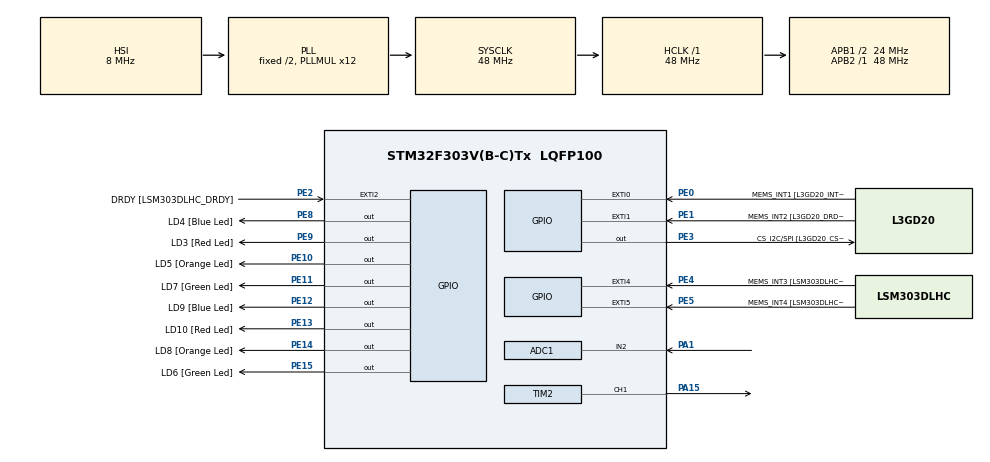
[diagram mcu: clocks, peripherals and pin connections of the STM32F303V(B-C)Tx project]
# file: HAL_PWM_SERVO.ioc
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ADC1.Channel-2\#ChannelRegularConversion=ADC_CHANNEL_2
ADC1.ContinuousConvMode=DISABLE
ADC1.DMAContinuousRequests=ENABLE
ADC1.EnableInjectedConversion=DISABLE
ADC1.ExternalTrigConv=ADC_EXTERNALTRIGCONV_T4_CC4
ADC1.NbrOfConversionFlag=1
ADC1.Offset-2\#ChannelRegularConversion=0
ADC1.OffsetNumber-2\#ChannelRegularConversion=ADC_OFFSET_NONE
ADC1.Rank-2\#ChannelRegularConversion=1
ADC1.Rank1_Channel=ADC_CHANNEL_2
ADC1.SamplingTime-2\#ChannelRegularConversion=ADC_SAMPLETIME_19CYCLES_5
ADC1.SamplingTimeOPAMP-2\#ChannelRegularConversion=ADC_SAMPLETIME_19CYCLES_5
ADC1.master=1
Dma.ADC1.0.Direction=DMA_PERIPH_TO_MEMORY
Dma.ADC1.0.Instance=DMA1_Channel1
Dma.ADC1.0.MemDataAlignment=DMA_MDATAALIGN_HALFWORD
Dma.ADC1.0.MemInc=DMA_MINC_DISABLE
Dma.ADC1.0.Mode=DMA_CIRCULAR
Dma.ADC1.0.PeriphDataAlignment=DMA_PDATAALIGN_HALFWORD
Dma.ADC1.0.PeriphInc=DMA_PINC_DISABLE
Dma.ADC1.0.Priority=DMA_PRIORITY_LOW
Dma.Request0=ADC1
Mcu.Family=STM32F3
Mcu.Name=STM32F303V(B-C)Tx
Mcu.Package=LQFP100
NVIC.DMA1_Channel1_IRQn=true\:0\:0\:false\:false\:true\:false\:true\:true
NVIC.PriorityGroup=NVIC_PRIORITYGROUP_0
NVIC.TIM4_IRQn=true\:0\:0\:false\:false\:true\:true\:true\:true
PA1.Mode=IN2-Single-Ended
PA1.Signal=ADC1_IN2
PA11.GPIO_Label=DM
PA11.Signal=USB_DM
PA12.GPIO_Label=DP
PA12.Signal=USB_DP
PA13.GPIO_Label=SWDIO
PA13.Signal=SYS_JTMS-SWDIO
PA14.GPIO_Label=SWCLK
PA14.Signal=SYS_JTCK-SWCLK
PA15.Signal=S_TIM2_CH1_ETR
PA5.GPIO_Label=SPI1_SCK [L3GD20_SCL/SPC]
PA5.GPIO_Mode=GPIO_MODE_AF_PP
PA5.GPIO_PuPd=GPIO_NOPULL
PA5.GPIO_Speed=GPIO_SPEED_FREQ_LOW
PA5.Signal=SPI1_SCK
PA6.GPIO_Label=SPI1_MISO [L3GD20_SA0/SDO]
PA6.GPIO_Mode=GPIO_MODE_AF_PP
PA6.GPIO_PuPd=GPIO_NOPULL
PA6.GPIO_Speed=GPIO_SPEED_FREQ_LOW
PA6.Signal=SPI1_MISO
PA7.GPIO_Label=SPI1_MISO [L3GD20_SDA/SDI/SDO]
PA7.GPIO_Mode=GPIO_MODE_AF_PP
PA7.GPIO_PuPd=GPIO_NOPULL
PA7.GPIO_Speed=GPIO_SPEED_FREQ_LOW
PA7.Signal=SPI1_MOSI
PB3.GPIO_Label=SWO
PB3.Signal=SYS_JTDO-TRACESWO
PB6.GPIO_FM6=__NULL
PB6.GPIO_Label=I2C1_SCL [LSM303DLHC_SCL]
PB6.GPIO_Mode=GPIO_MODE_AF_OD
PB6.GPIO_PuPd=GPIO_NOPULL
PB6.GPIO_Speed=GPIO_SPEED_FREQ_LOW
PB6.Signal=I2C1_SCL
PB7.GPIO_FM7=__NULL
PB7.GPIO_Label=I2C1_SDA [LSM303DLHC_SDA]
PB7.GPIO_Mode=GPIO_MODE_AF_OD
PB7.GPIO_PuPd=GPIO_NOPULL
PB7.GPIO_Speed=GPIO_SPEED_FREQ_LOW
PB7.Signal=I2C1_SDA
PC14-OSC32_IN.GPIO_Label=OSC32_IN
PC14-OSC32_IN.Signal=RCC_OSC32_IN
PC15-OSC32_OUT.GPIO_Label=OSC32_OUT
PC15-OSC32_OUT.Signal=RCC_OSC32_OUT
PE0.GPIO_Label=MEMS_INT1 [L3GD20_INT1]
PE0.GPIO_ModeDefaultEXTI=GPIO_MODE_EVT_RISING
PE0.GPIO_PuPd=GPIO_NOPULL
PE0.Signal=GPXTI0
PE1.GPIO_Label=MEMS_INT2 [L3GD20_DRDY/INT2]
PE1.GPIO_ModeDefaultEXTI=GPIO_MODE_EVT_RISING
PE1.GPIO_PuPd=GPIO_NOPULL
PE1.Signal=GPXTI1
PE10.GPIO_Label=LD5 [Orange Led]
PE10.GPIO_ModeDefaultOutputPP=GPIO_MODE_OUTPUT_PP
PE10.GPIO_PuPd=GPIO_NOPULL
PE10.GPIO_Speed=GPIO_SPEED_FREQ_LOW
PE10.Signal=GPIO_Output
PE11.GPIO_Label=LD7 [Green Led]
PE11.GPIO_ModeDefaultOutputPP=GPIO_MODE_OUTPUT_PP
PE11.GPIO_PuPd=GPIO_NOPULL
PE11.GPIO_Speed=GPIO_SPEED_FREQ_LOW
PE11.Signal=GPIO_Output
PE12.GPIO_Label=LD9 [Blue Led]
PE12.GPIO_ModeDefaultOutputPP=GPIO_MODE_OUTPUT_PP
PE12.GPIO_PuPd=GPIO_NOPULL
PE12.GPIO_Speed=GPIO_SPEED_FREQ_LOW
PE12.Signal=GPIO_Output
PE13.GPIO_Label=LD10 [Red Led]
PE13.GPIO_ModeDefaultOutputPP=GPIO_MODE_OUTPUT_PP
PE13.GPIO_PuPd=GPIO_NOPULL
PE13.GPIO_Speed=GPIO_SPEED_FREQ_LOW
PE13.Signal=GPIO_Output
PE14.GPIO_Label=LD8 [Orange Led]
PE14.GPIO_ModeDefaultOutputPP=GPIO_MODE_OUTPUT_PP
PE14.GPIO_PuPd=GPIO_NOPULL
PE14.GPIO_Speed=GPIO_SPEED_FREQ_LOW
PE14.Signal=GPIO_Output
PE15.GPIO_Label=LD6 [Green Led]
PE15.GPIO_ModeDefaultOutputPP=GPIO_MODE_OUTPUT_PP
PE15.GPIO_PuPd=GPIO_NOPULL
PE15.GPIO_Speed=GPIO_SPEED_FREQ_LOW
PE15.Signal=GPIO_Output
PE2.GPIO_Label=DRDY [LSM303DLHC_DRDY]
PE2.GPIO_ModeDefaultEXTI=GPIO_MODE_EVT_RISING
PE2.GPIO_PuPd=GPIO_NOPULL
PE2.Signal=GPXTI2
PE3.GPIO_Label=CS_I2C/SPI [L3GD20_CS_I2C/SPI]
PE3.GPIO_ModeDefaultOutputPP=GPIO_MODE_OUTPUT_PP
PE3.GPIO_PuPd=GPIO_NOPULL
PE3.GPIO_Speed=GPIO_SPEED_FREQ_LOW
PE3.Signal=GPIO_Output
PE4.GPIO_Label=MEMS_INT3 [LSM303DLHC_INT1]
PE4.GPIO_ModeDefaultEXTI=GPIO_MODE_EVT_RISING
PE4.GPIO_PuPd=GPIO_NOPULL
PE4.Signal=GPXTI4
PE5.GPIO_Label=MEMS_INT4 [LSM303DLHC_INT2]
PE5.GPIO_ModeDefaultEXTI=GPIO_MODE_EVT_RISING
PE5.GPIO_PuPd=GPIO_NOPULL
PE5.Signal=GPXTI5
PE8.GPIO_Label=LD4 [Blue Led]
PE8.GPIO_ModeDefaultOutputPP=GPIO_MODE_OUTPUT_PP
PE8.GPIO_PuPd=GPIO_NOPULL
PE8.GPIO_Speed=GPIO_SPEED_FREQ_LOW
PE8.Signal=GPIO_Output
PE9.GPIO_Label=LD3 [Red Led]
PE9.GPIO_ModeDefaultOutputPP=GPIO_MODE_OUTPUT_PP
PE9.GPIO_PuPd=GPIO_NOPULL
PE9.GPIO_Speed=GPIO_SPEED_FREQ_LOW
PE9.Signal=GPIO_Output
PF0-OSC_IN.GPIO_Label=OSC_IN
PF0-OSC_IN.Signal=RCC_OSC_IN
PF1-OSC_OUT.GPIO_Label=OSC_OUT
PF1-OSC_OUT.Signal=RCC_OSC_OUT
ProjectManager.HeapSize=0x200
ProjectManager.StackSize=0x400
ProjectManager.TargetToolchain=STM32CubeIDE
RCC.AHBFreq_Value=48000000
RCC.APB1CLKDivider=RCC_HCLK_DIV2
RCC.APB1Freq_Value=24000000
RCC.APB1TimFreq_Value=48000000
RCC.APB2Freq_Value=48000000
RCC.APB2TimFreq_Value=48000000
RCC.CortexFreq_Value=48000000
RCC.HCLKFreq_Value=48000000
RCC.HSE_VALUE=8000000
RCC.HSI_VALUE=8000000
RCC.LSE_VALUE=32768
RCC.PLLMUL=RCC_PLL_MUL12
RCC.SYSCLKFreq_VALUE=48000000
RCC.SYSCLKSourceVirtual=RCC_SYSCLKSOURCE_PLLCLK
RCC.USBFreq_Value=48000000
SH.S_TIM2_CH1_ETR.0=TIM2_CH1,PWM Generation1 CH1
TIM2.AutoReloadPreload=TIM_AUTORELOAD_PRELOAD_ENABLE
TIM2.Channel-PWM\ Generation1\ CH1=TIM_CHANNEL_1
TIM2.OC1Preload_PWM=ENABLE
TIM2.OCFastMode_PWM-PWM\ Generation1\ CH1=TIM_OCFAST_DISABLE
TIM2.Period=20119
TIM2.Prescaler=47
TIM2.Pulse-PWM\ Generation1\ CH1=99
TIM4.AutoReloadPreload=TIM_AUTORELOAD_PRELOAD_ENABLE
TIM4.Channel-Output\ Compare4\ No\ Output=TIM_CHANNEL_4
TIM4.ClearChannel4=TIM_CHANNEL_4
TIM4.ClearInputSource=TIM_CLEARINPUTSOURCE_NONE
TIM4.OC4Preload=ENABLE
TIM4.OCMode_4=TIM_OCMODE_TOGGLE
TIM4.OCPolarity_4=TIM_OCPOLARITY_LOW
TIM4.Period=100
TIM4.Prescaler=4800
TIM4.Pulse-Output\ Compare4\ No\ Output=50
VP_TIM2_VS_ClockSourceINT.Mode=Internal
VP_TIM4_VS_ClockSourceINT.Mode=Internal
VP_TIM4_VS_no_output4.Mode=Output Compare4 No Output
board=STM32F3DISCOVERY

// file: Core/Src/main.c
/* USER CODE BEGIN Header */
/**
  ******************************************************************************
  * @file           : main.c
  * @brief          : Main program body
  ******************************************************************************
  * @attention
  *
  * Copyright (c) 2024 STMicroelectronics.
  * All rights reserved.
  *
  * This software is licensed under terms that can be found in the LICENSE file
  * in the root directory of this software component.
  * If no LICENSE file comes with this software, it is provided AS-IS.
  *
  ******************************************************************************
  */
/* USER CODE END Header */
#include "main.h"

/* USER CODE BEGIN Includes */
#include <MY_motor.h>

/* USER CODE END Includes */

/* USER CODE BEGIN PTD */
#define DELAY_TIME 1
/* USER CODE END PTD */

/* USER CODE BEGIN PD */
extern long _map(long x, long in_min, long in_max, long out_min, long out_max);
/* USER CODE END PD */

ADC_HandleTypeDef hadc1;
DMA_HandleTypeDef hdma_adc1;

TIM_HandleTypeDef htim2;
TIM_HandleTypeDef htim4;

void SystemClock_Config(void);
static void MX_GPIO_Init(void);
static void MX_DMA_Init(void);
static void MX_TIM2_Init(void);
static void MX_ADC1_Init(void);
static void MX_TIM4_Init(void);

int main(void)
{

  /* MCU Configuration--------------------------------------------------------*/

  /* Reset of all peripherals, Initializes the Flash interface and the Systick. */
  HAL_Init();

  /* Configure the system clock */
  SystemClock_Config();

  /* Initialize all configured peripherals */
  MX_GPIO_Init();
  MX_DMA_Init();
  MX_TIM2_Init();
  MX_ADC1_Init();
  MX_TIM4_Init();
  /* USER CODE BEGIN 2 */
  //START PWM MODE
  HAL_TIM_PWM_Start(&htim2, TIM_CHANNEL_1);
  HAL_TIM_OC_Start(&htim4, TIM_CHANNEL_4);

  //CHANGE THE WIDTH in %
  //PWM_width_change(&htim2, TIM_CHANNEL_1, 25);

  uint16_t ADC_result = 0;
  uint8_t res = 0;
  HAL_ADC_Start_DMA(&hadc1, (uint32_t*)&ADC_result, 1);

  /* USER CODE END 2 */

  /* Infinite loop */
  /* USER CODE BEGIN WHILE */
  while (1)
  {

	  res = _map(ADC_result, 0, 4094, 0, 180);
	  SERVO_set(&htim2, res);
	 // HAL_Delay(DELAY_TIME);

    /* USER CODE END WHILE */

  }
}

void SystemClock_Config(void)
{
  RCC_OscInitTypeDef RCC_OscInitStruct = {0};
  RCC_ClkInitTypeDef RCC_ClkInitStruct = {0};
  RCC_PeriphCLKInitTypeDef PeriphClkInit = {0};

  /** Initializes the RCC Oscillators according to the specified parameters
  * in the RCC_OscInitTypeDef structure.
  */
  RCC_OscInitStruct.OscillatorType = RCC_OSCILLATORTYPE_HSI;
  RCC_OscInitStruct.HSIState = RCC_HSI_ON;
  RCC_OscInitStruct.HSICalibrationValue = RCC_HSICALIBRATION_DEFAULT;
  RCC_OscInitStruct.PLL.PLLState = RCC_PLL_ON;
  RCC_OscInitStruct.PLL.PLLSource = RCC_PLLSOURCE_HSI;
  RCC_OscInitStruct.PLL.PLLMUL = RCC_PLL_MUL12;
  if (HAL_RCC_OscConfig(&RCC_OscInitStruct) != HAL_OK)
  {
    Error_Handler();
  }

  /** Initializes the CPU, AHB and APB buses clocks
  */
  RCC_ClkInitStruct.ClockType = RCC_CLOCKTYPE_HCLK|RCC_CLOCKTYPE_SYSCLK
                              |RCC_CLOCKTYPE_PCLK1|RCC_CLOCKTYPE_PCLK2;
  RCC_ClkInitStruct.SYSCLKSource = RCC_SYSCLKSOURCE_PLLCLK;
  RCC_ClkInitStruct.AHBCLKDivider = RCC_SYSCLK_DIV1;
  RCC_ClkInitStruct.APB1CLKDivider = RCC_HCLK_DIV2;
  RCC_ClkInitStruct.APB2CLKDivider = RCC_HCLK_DIV1;

  if (HAL_RCC_ClockConfig(&RCC_ClkInitStruct, FLASH_LATENCY_1) != HAL_OK)
  {
    Error_Handler();
  }
  PeriphClkInit.PeriphClockSelection = RCC_PERIPHCLK_ADC12;
  PeriphClkInit.Adc12ClockSelection = RCC_ADC12PLLCLK_DIV1;
  if (HAL_RCCEx_PeriphCLKConfig(&PeriphClkInit) != HAL_OK)
  {
    Error_Handler();
  }
}

static void MX_ADC1_Init(void)
{

  ADC_MultiModeTypeDef multimode = {0};
  ADC_ChannelConfTypeDef sConfig = {0};

  /** Common config
  */
  hadc1.Instance = ADC1;
  hadc1.Init.ClockPrescaler = ADC_CLOCK_ASYNC_DIV1;
  hadc1.Init.Resolution = ADC_RESOLUTION_12B;
  hadc1.Init.ScanConvMode = ADC_SCAN_DISABLE;
  hadc1.Init.ContinuousConvMode = DISABLE;
  hadc1.Init.DiscontinuousConvMode = DISABLE;
  hadc1.Init.ExternalTrigConvEdge = ADC_EXTERNALTRIGCONVEDGE_RISING;
  hadc1.Init.ExternalTrigConv = ADC_EXTERNALTRIGCONV_T4_CC4;
  hadc1.Init.DataAlign = ADC_DATAALIGN_RIGHT;
  hadc1.Init.NbrOfConversion = 1;
  hadc1.Init.DMAContinuousRequests = ENABLE;
  hadc1.Init.EOCSelection = ADC_EOC_SINGLE_CONV;
  hadc1.Init.LowPowerAutoWait = DISABLE;
  hadc1.Init.Overrun = ADC_OVR_DATA_OVERWRITTEN;
  if (HAL_ADC_Init(&hadc1) != HAL_OK)
  {
    Error_Handler();
  }

  /** Configure the ADC multi-mode
  */
  multimode.Mode = ADC_MODE_INDEPENDENT;
  if (HAL_ADCEx_MultiModeConfigChannel(&hadc1, &multimode) != HAL_OK)
  {
    Error_Handler();
  }

  /** Configure Regular Channel
  */
  sConfig.Channel = ADC_CHANNEL_2;
  sConfig.Rank = ADC_REGULAR_RANK_1;
  sConfig.SingleDiff = ADC_SINGLE_ENDED;
  sConfig.SamplingTime = ADC_SAMPLETIME_19CYCLES_5;
  sConfig.OffsetNumber = ADC_OFFSET_NONE;
  sConfig.Offset = 0;
  if (HAL_ADC_ConfigChannel(&hadc1, &sConfig) != HAL_OK)
  {
    Error_Handler();
  }

}

static void MX_TIM2_Init(void)
{

  TIM_ClockConfigTypeDef sClockSourceConfig = {0};
  TIM_MasterConfigTypeDef sMasterConfig = {0};
  TIM_OC_InitTypeDef sConfigOC = {0};

  htim2.Instance = TIM2;
  htim2.Init.Prescaler = 47;
  htim2.Init.CounterMode = TIM_COUNTERMODE_UP;
  htim2.Init.Period = 20119;
  htim2.Init.ClockDivision = TIM_CLOCKDIVISION_DIV1;
  htim2.Init.AutoReloadPreload = TIM_AUTORELOAD_PRELOAD_ENABLE;
  if (HAL_TIM_Base_Init(&htim2) != HAL_OK)
  {
    Error_Handler();
  }
  sClockSourceConfig.ClockSource = TIM_CLOCKSOURCE_INTERNAL;
  if (HAL_TIM_ConfigClockSource(&htim2, &sClockSourceConfig) != HAL_OK)
  {
    Error_Handler();
  }
  if (HAL_TIM_PWM_Init(&htim2) != HAL_OK)
  {
    Error_Handler();
  }
  sMasterConfig.MasterOutputTrigger = TIM_TRGO_RESET;
  sMasterConfig.MasterSlaveMode = TIM_MASTERSLAVEMODE_DISABLE;
  if (HAL_TIMEx_MasterConfigSynchronization(&htim2, &sMasterConfig) != HAL_OK)
  {
    Error_Handler();
  }
  sConfigOC.OCMode = TIM_OCMODE_PWM1;
  sConfigOC.Pulse = 99;
  sConfigOC.OCPolarity = TIM_OCPOLARITY_HIGH;
  sConfigOC.OCFastMode = TIM_OCFAST_DISABLE;
  if (HAL_TIM_PWM_ConfigChannel(&htim2, &sConfigOC, TIM_CHANNEL_1) != HAL_OK)
  {
    Error_Handler();
  }
  HAL_TIM_MspPostInit(&htim2);

}

static void MX_TIM4_Init(void)
{

  TIM_ClockConfigTypeDef sClockSourceConfig = {0};
  TIM_MasterConfigTypeDef sMasterConfig = {0};
  TIM_OC_InitTypeDef sConfigOC = {0};

  htim4.Instance = TIM4;
  htim4.Init.Prescaler = 4800;
  htim4.Init.CounterMode = TIM_COUNTERMODE_UP;
  htim4.Init.Period = 100;
  htim4.Init.ClockDivision = TIM_CLOCKDIVISION_DIV1;
  htim4.Init.AutoReloadPreload = TIM_AUTORELOAD_PRELOAD_ENABLE;
  if (HAL_TIM_Base_Init(&htim4) != HAL_OK)
  {
    Error_Handler();
  }
  sClockSourceConfig.ClockSource = TIM_CLOCKSOURCE_INTERNAL;
  if (HAL_TIM_ConfigClockSource(&htim4, &sClockSourceConfig) != HAL_OK)
  {
    Error_Handler();
  }
  if (HAL_TIM_OC_Init(&htim4) != HAL_OK)
  {
    Error_Handler();
  }
  sMasterConfig.MasterOutputTrigger = TIM_TRGO_RESET;
  sMasterConfig.MasterSlaveMode = TIM_MASTERSLAVEMODE_DISABLE;
  if (HAL_TIMEx_MasterConfigSynchronization(&htim4, &sMasterConfig) != HAL_OK)
  {
    Error_Handler();
  }
  sConfigOC.OCMode = TIM_OCMODE_TOGGLE;
  sConfigOC.Pulse = 50;
  sConfigOC.OCPolarity = TIM_OCPOLARITY_LOW;
  sConfigOC.OCFastMode = TIM_OCFAST_DISABLE;
  if (HAL_TIM_OC_ConfigChannel(&htim4, &sConfigOC, TIM_CHANNEL_4) != HAL_OK)
  {
    Error_Handler();
  }
  __HAL_TIM_ENABLE_OCxPRELOAD(&htim4, TIM_CHANNEL_4);

}

static void MX_DMA_Init(void)
{

  /* DMA controller clock enable */
  __HAL_RCC_DMA1_CLK_ENABLE();

  /* DMA interrupt init */
  /* DMA1_Channel1_IRQn interrupt configuration */
  HAL_NVIC_SetPriority(DMA1_Channel1_IRQn, 0, 0);
  HAL_NVIC_EnableIRQ(DMA1_Channel1_IRQn);

}

static void MX_GPIO_Init(void)
{
  GPIO_InitTypeDef GPIO_InitStruct = {0};

  /* GPIO Ports Clock Enable */
  __HAL_RCC_GPIOE_CLK_ENABLE();
  __HAL_RCC_GPIOC_CLK_ENABLE();
  __HAL_RCC_GPIOF_CLK_ENABLE();
  __HAL_RCC_GPIOA_CLK_ENABLE();
  __HAL_RCC_GPIOB_CLK_ENABLE();

  /*Configure GPIO pin Output Level */
  HAL_GPIO_WritePin(GPIOE, CS_I2C_SPI_Pin|LD4_Pin|LD3_Pin|LD5_Pin
                          |LD7_Pin|LD9_Pin|LD10_Pin|LD8_Pin
                          |LD6_Pin, GPIO_PIN_RESET);

  /*Configure GPIO pins : DRDY_Pin MEMS_INT3_Pin MEMS_INT4_Pin MEMS_INT1_Pin
                           MEMS_INT2_Pin */
  GPIO_InitStruct.Pin = DRDY_Pin|MEMS_INT3_Pin|MEMS_INT4_Pin|MEMS_INT1_Pin
                          |MEMS_INT2_Pin;
  GPIO_InitStruct.Mode = GPIO_MODE_EVT_RISING;
  GPIO_InitStruct.Pull = GPIO_NOPULL;
  HAL_GPIO_Init(GPIOE, &GPIO_InitStruct);

  /*Configure GPIO pins : CS_I2C_SPI_Pin LD4_Pin LD3_Pin LD5_Pin
                           LD7_Pin LD9_Pin LD10_Pin LD8_Pin
                           LD6_Pin */
  GPIO_InitStruct.Pin = CS_I2C_SPI_Pin|LD4_Pin|LD3_Pin|LD5_Pin
                          |LD7_Pin|LD9_Pin|LD10_Pin|LD8_Pin
                          |LD6_Pin;
  GPIO_InitStruct.Mode = GPIO_MODE_OUTPUT_PP;
  GPIO_InitStruct.Pull = GPIO_NOPULL;
  GPIO_InitStruct.Speed = GPIO_SPEED_FREQ_LOW;
  HAL_GPIO_Init(GPIOE, &GPIO_InitStruct);

  /*Configure GPIO pins : SPI1_SCK_Pin SPI1_MISO_Pin SPI1_MISOA7_Pin */
  GPIO_InitStruct.Pin = SPI1_SCK_Pin|SPI1_MISO_Pin|SPI1_MISOA7_Pin;
  GPIO_InitStruct.Mode = GPIO_MODE_AF_PP;
  GPIO_InitStruct.Pull = GPIO_NOPULL;
  GPIO_InitStruct.Speed = GPIO_SPEED_FREQ_LOW;
  GPIO_InitStruct.Alternate = GPIO_AF5_SPI1;
  HAL_GPIO_Init(GPIOA, &GPIO_InitStruct);

  /*Configure GPIO pins : DM_Pin DP_Pin */
  GPIO_InitStruct.Pin = DM_Pin|DP_Pin;
  GPIO_InitStruct.Mode = GPIO_MODE_AF_PP;
  GPIO_InitStruct.Pull = GPIO_NOPULL;
  GPIO_InitStruct.Speed = GPIO_SPEED_FREQ_HIGH;
  GPIO_InitStruct.Alternate = GPIO_AF14_USB;
  HAL_GPIO_Init(GPIOA, &GPIO_InitStruct);

  /*Configure GPIO pins : I2C1_SCL_Pin I2C1_SDA_Pin */
  GPIO_InitStruct.Pin = I2C1_SCL_Pin|I2C1_SDA_Pin;
  GPIO_InitStruct.Mode = GPIO_MODE_AF_OD;
  GPIO_InitStruct.Pull = GPIO_NOPULL;
  GPIO_InitStruct.Speed = GPIO_SPEED_FREQ_LOW;
  GPIO_InitStruct.Alternate = GPIO_AF4_I2C1;
  HAL_GPIO_Init(GPIOB, &GPIO_InitStruct);

}

void Error_Handler(void)
{
  __disable_irq();
  while (1)
  {
  }
}
